# ESP32-S31 register map
Vendor: ESPRESSIF SYSTEMS (SHANGHAI) CO., LTD.; Series: ESP32 S-Series; File version: 1
CPU: RV32IMAFC r0p0, little endian, no MPU, FPU, 0 interrupt priority bits
Address unit: 32 bits
Registers are 32-bit, read-write, reset 0x0 unless marked. A register's access mark holds for its fields unless they carry their own. Offsets are from the block's base; [hi:lo] are bit positions.

## HP_PERI0_PMS — HP_PERI0_PMS Peripheral
Base 0x20505000
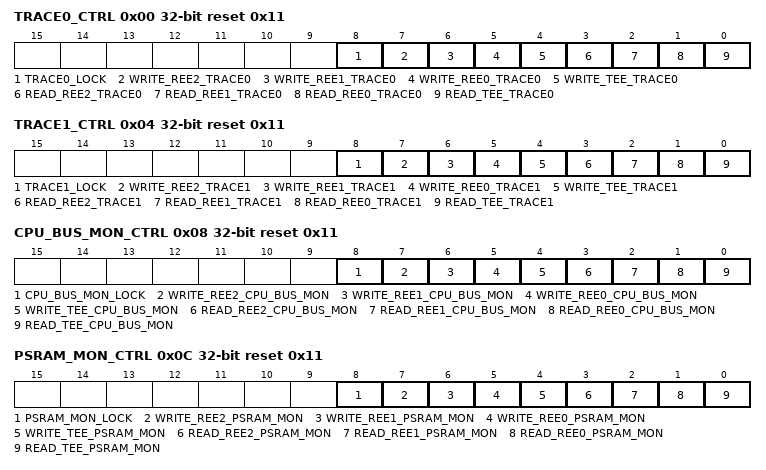
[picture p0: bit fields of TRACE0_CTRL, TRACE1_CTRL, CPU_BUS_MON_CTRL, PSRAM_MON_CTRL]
0x00 TRACE0_CTRL reset 0x11 — trace0 read/write control register
  [8] TRACE0_LOCK — Set 1 to lock trace0 peri_apm configuration
  [7] WRITE_REE2_TRACE0 — Configures trace0 registers write permission in ree2 mode.\\ 0: can not be write \\ 1: can be write \\
  [6] WRITE_REE1_TRACE0 — Configures trace0 registers write permission in ree1 mode.\\ 0: can not be write \\ 1: can be write \\
  [5] WRITE_REE0_TRACE0 — Configures trace0 registers write permission in ree0 mode.\\ 0: can not be write \\ 1: can be write \\
  [4] WRITE_TEE_TRACE0 — Configures trace0 registers write permission in tee mode.\\ 0: can not be write \\ 1: can be write \\
  [3] READ_REE2_TRACE0 — Configures trace0 registers read permission in ree2 mode.\\ 0: can not be read \\ 1: can be read \\
  [2] READ_REE1_TRACE0 — Configures trace0 registers read permission in ree1 mode.\\ 0: can not be read \\ 1: can be read \\
  [1] READ_REE0_TRACE0 — Configures trace0 registers read permission in ree0 mode.\\ 0: can not be read \\ 1: can be read \\
  [0] READ_TEE_TRACE0 — Configures trace0 registers read permission in tee mode.\\ 0: can not be read \\ 1: can be read \\
0x04 TRACE1_CTRL reset 0x11 — trace1 read/write control register
  [8] TRACE1_LOCK — Set 1 to lock trace1 peri_apm configuration
  [7] WRITE_REE2_TRACE1 — Configures trace1 registers write permission in ree2 mode.\\ 0: can not be write \\ 1: can be write \\
  [6] WRITE_REE1_TRACE1 — Configures trace1 registers write permission in ree1 mode.\\ 0: can not be write \\ 1: can be write \\
  [5] WRITE_REE0_TRACE1 — Configures trace1 registers write permission in ree0 mode.\\ 0: can not be write \\ 1: can be write \\
  [4] WRITE_TEE_TRACE1 — Configures trace1 registers write permission in tee mode.\\ 0: can not be write \\ 1: can be write \\
  [3] READ_REE2_TRACE1 — Configures trace1 registers read permission in ree2 mode.\\ 0: can not be read \\ 1: can be read \\
  [2] READ_REE1_TRACE1 — Configures trace1 registers read permission in ree1 mode.\\ 0: can not be read \\ 1: can be read \\
  [1] READ_REE0_TRACE1 — Configures trace1 registers read permission in ree0 mode.\\ 0: can not be read \\ 1: can be read \\
  [0] READ_TEE_TRACE1 — Configures trace1 registers read permission in tee mode.\\ 0: can not be read \\ 1: can be read \\
0x08 CPU_BUS_MON_CTRL reset 0x11 — cpu_bus_mon read/write control register
  [8] CPU_BUS_MON_LOCK — Set 1 to lock cpu_bus_mon peri_apm configuration
  [7] WRITE_REE2_CPU_BUS_MON — Configures cpu_bus_mon registers write permission in ree2 mode.\\ 0: can not be write \\ 1: can be write \\
  [6] WRITE_REE1_CPU_BUS_MON — Configures cpu_bus_mon registers write permission in ree1 mode.\\ 0: can not be write \\ 1: can be write \\
  [5] WRITE_REE0_CPU_BUS_MON — Configures cpu_bus_mon registers write permission in ree0 mode.\\ 0: can not be write \\ 1: can be write \\
  [4] WRITE_TEE_CPU_BUS_MON — Configures cpu_bus_mon registers write permission in tee mode.\\ 0: can not be write \\ 1: can be write \\
  [3] READ_REE2_CPU_BUS_MON — Configures cpu_bus_mon registers read permission in ree2 mode.\\ 0: can not be read \\ 1: can be read \\
  [2] READ_REE1_CPU_BUS_MON — Configures cpu_bus_mon registers read permission in ree1 mode.\\ 0: can not be read \\ 1: can be read \\
  [1] READ_REE0_CPU_BUS_MON — Configures cpu_bus_mon registers read permission in ree0 mode.\\ 0: can not be read \\ 1: can be read \\
  [0] READ_TEE_CPU_BUS_MON — Configures cpu_bus_mon registers read permission in tee mode.\\ 0: can not be read \\ 1: can be read \\
0x0C PSRAM_MON_CTRL reset 0x11 — psram_mon read/write control register
  [8] PSRAM_MON_LOCK — Set 1 to lock psram_mon peri_apm configuration
  [7] WRITE_REE2_PSRAM_MON — Configures psram_mon registers write permission in ree2 mode.\\ 0: can not be write \\ 1: can be write \\
  [6] WRITE_REE1_PSRAM_MON — Configures psram_mon registers write permission in ree1 mode.\\ 0: can not be write \\ 1: can be write \\
  [5] WRITE_REE0_PSRAM_MON — Configures psram_mon registers write permission in ree0 mode.\\ 0: can not be write \\ 1: can be write \\
  [4] WRITE_TEE_PSRAM_MON — Configures psram_mon registers write permission in tee mode.\\ 0: can not be write \\ 1: can be write \\
  [3] READ_REE2_PSRAM_MON — Configures psram_mon registers read permission in ree2 mode.\\ 0: can not be read \\ 1: can be read \\
  [2] READ_REE1_PSRAM_MON — Configures psram_mon registers read permission in ree1 mode.\\ 0: can not be read \\ 1: can be read \\
  [1] READ_REE0_PSRAM_MON — Configures psram_mon registers read permission in ree0 mode.\\ 0: can not be read \\ 1: can be read \\
  [0] READ_TEE_PSRAM_MON — Configures psram_mon registers read permission in tee mode.\\ 0: can not be read \\ 1: can be read \\
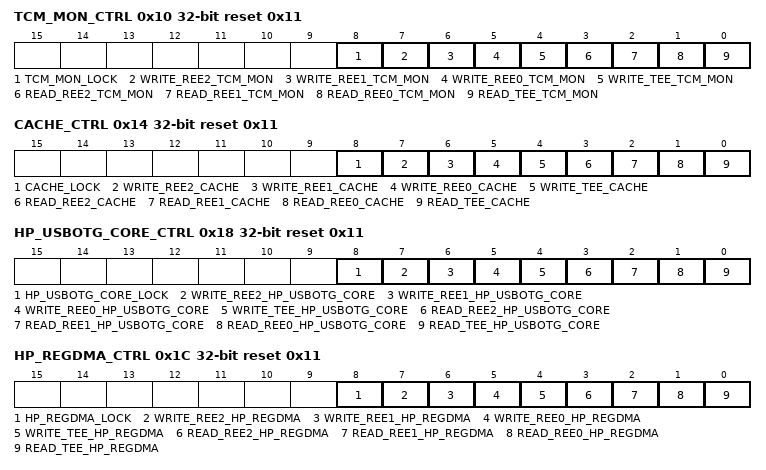
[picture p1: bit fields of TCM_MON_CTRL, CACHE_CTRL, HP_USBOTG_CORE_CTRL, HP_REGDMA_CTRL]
0x10 TCM_MON_CTRL reset 0x11 — tcm_mon read/write control register
  [8] TCM_MON_LOCK — Set 1 to lock tcm_mon peri_apm configuration
  [7] WRITE_REE2_TCM_MON — Configures tcm_mon registers write permission in ree2 mode.\\ 0: can not be write \\ 1: can be write \\
  [6] WRITE_REE1_TCM_MON — Configures tcm_mon registers write permission in ree1 mode.\\ 0: can not be write \\ 1: can be write \\
  [5] WRITE_REE0_TCM_MON — Configures tcm_mon registers write permission in ree0 mode.\\ 0: can not be write \\ 1: can be write \\
  [4] WRITE_TEE_TCM_MON — Configures tcm_mon registers write permission in tee mode.\\ 0: can not be write \\ 1: can be write \\
  [3] READ_REE2_TCM_MON — Configures tcm_mon registers read permission in ree2 mode.\\ 0: can not be read \\ 1: can be read \\
  [2] READ_REE1_TCM_MON — Configures tcm_mon registers read permission in ree1 mode.\\ 0: can not be read \\ 1: can be read \\
  [1] READ_REE0_TCM_MON — Configures tcm_mon registers read permission in ree0 mode.\\ 0: can not be read \\ 1: can be read \\
  [0] READ_TEE_TCM_MON — Configures tcm_mon registers read permission in tee mode.\\ 0: can not be read \\ 1: can be read \\
0x14 CACHE_CTRL reset 0x11 — cache read/write control register
  [8] CACHE_LOCK — Set 1 to lock cache peri_apm configuration
  [7] WRITE_REE2_CACHE — Configures cache registers write permission in ree2 mode.\\ 0: can not be write \\ 1: can be write \\
  [6] WRITE_REE1_CACHE — Configures cache registers write permission in ree1 mode.\\ 0: can not be write \\ 1: can be write \\
  [5] WRITE_REE0_CACHE — Configures cache registers write permission in ree0 mode.\\ 0: can not be write \\ 1: can be write \\
  [4] WRITE_TEE_CACHE — Configures cache registers write permission in tee mode.\\ 0: can not be write \\ 1: can be write \\
  [3] READ_REE2_CACHE — Configures cache registers read permission in ree2 mode.\\ 0: can not be read \\ 1: can be read \\
  [2] READ_REE1_CACHE — Configures cache registers read permission in ree1 mode.\\ 0: can not be read \\ 1: can be read \\
  [1] READ_REE0_CACHE — Configures cache registers read permission in ree0 mode.\\ 0: can not be read \\ 1: can be read \\
  [0] READ_TEE_CACHE — Configures cache registers read permission in tee mode.\\ 0: can not be read \\ 1: can be read \\
0x18 HP_USBOTG_CORE_CTRL reset 0x11 — hp_usbotg_core read/write control register
  [8] HP_USBOTG_CORE_LOCK — Set 1 to lock hp_usbotg_core peri_apm configuration
  [7] WRITE_REE2_HP_USBOTG_CORE — Configures hp_usbotg_core registers write permission in ree2 mode.\\ 0: can not be write \\ 1: can be write \\
  [6] WRITE_REE1_HP_USBOTG_CORE — Configures hp_usbotg_core registers write permission in ree1 mode.\\ 0: can not be write \\ 1: can be write \\
  [5] WRITE_REE0_HP_USBOTG_CORE — Configures hp_usbotg_core registers write permission in ree0 mode.\\ 0: can not be write \\ 1: can be write \\
  [4] WRITE_TEE_HP_USBOTG_CORE — Configures hp_usbotg_core registers write permission in tee mode.\\ 0: can not be write \\ 1: can be write \\
  [3] READ_REE2_HP_USBOTG_CORE — Configures hp_usbotg_core registers read permission in ree2 mode.\\ 0: can not be read \\ 1: can be read \\
  [2] READ_REE1_HP_USBOTG_CORE — Configures hp_usbotg_core registers read permission in ree1 mode.\\ 0: can not be read \\ 1: can be read \\
  [1] READ_REE0_HP_USBOTG_CORE — Configures hp_usbotg_core registers read permission in ree0 mode.\\ 0: can not be read \\ 1: can be read \\
  [0] READ_TEE_HP_USBOTG_CORE — Configures hp_usbotg_core registers read permission in tee mode.\\ 0: can not be read \\ 1: can be read \\
0x1C HP_REGDMA_CTRL reset 0x11 — hp_regdma read/write control register
  [8] HP_REGDMA_LOCK — Set 1 to lock hp_regdma peri_apm configuration
  [7] WRITE_REE2_HP_REGDMA — Configures hp_regdma registers write permission in ree2 mode.\\ 0: can not be write \\ 1: can be write \\
  [6] WRITE_REE1_HP_REGDMA — Configures hp_regdma registers write permission in ree1 mode.\\ 0: can not be write \\ 1: can be write \\
  [5] WRITE_REE0_HP_REGDMA — Configures hp_regdma registers write permission in ree0 mode.\\ 0: can not be write \\ 1: can be write \\
  [4] WRITE_TEE_HP_REGDMA — Configures hp_regdma registers write permission in tee mode.\\ 0: can not be write \\ 1: can be write \\
  [3] READ_REE2_HP_REGDMA — Configures hp_regdma registers read permission in ree2 mode.\\ 0: can not be read \\ 1: can be read \\
  [2] READ_REE1_HP_REGDMA — Configures hp_regdma registers read permission in ree1 mode.\\ 0: can not be read \\ 1: can be read \\
  [1] READ_REE0_HP_REGDMA — Configures hp_regdma registers read permission in ree0 mode.\\ 0: can not be read \\ 1: can be read \\
  [0] READ_TEE_HP_REGDMA — Configures hp_regdma registers read permission in tee mode.\\ 0: can not be read \\ 1: can be read \\
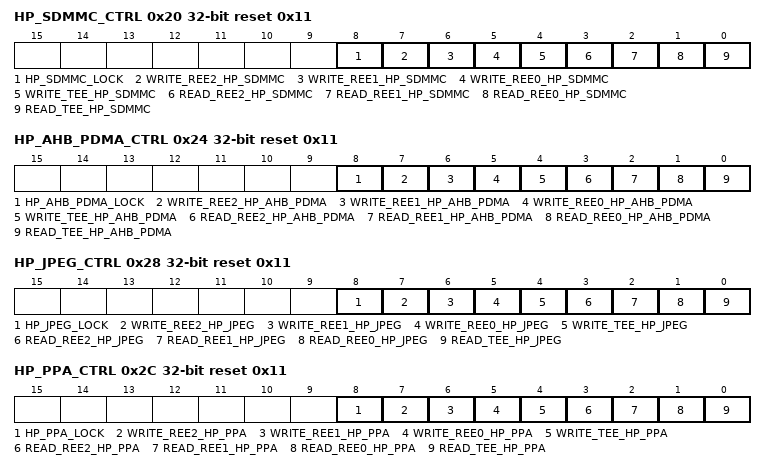
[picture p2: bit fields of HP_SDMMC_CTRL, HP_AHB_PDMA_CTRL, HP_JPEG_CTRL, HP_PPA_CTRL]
0x20 HP_SDMMC_CTRL reset 0x11 — hp_sdmmc read/write control register
  [8] HP_SDMMC_LOCK — Set 1 to lock hp_sdmmc peri_apm configuration
  [7] WRITE_REE2_HP_SDMMC — Configures hp_sdmmc registers write permission in ree2 mode.\\ 0: can not be write \\ 1: can be write \\
  [6] WRITE_REE1_HP_SDMMC — Configures hp_sdmmc registers write permission in ree1 mode.\\ 0: can not be write \\ 1: can be write \\
  [5] WRITE_REE0_HP_SDMMC — Configures hp_sdmmc registers write permission in ree0 mode.\\ 0: can not be write \\ 1: can be write \\
  [4] WRITE_TEE_HP_SDMMC — Configures hp_sdmmc registers write permission in tee mode.\\ 0: can not be write \\ 1: can be write \\
  [3] READ_REE2_HP_SDMMC — Configures hp_sdmmc registers read permission in ree2 mode.\\ 0: can not be read \\ 1: can be read \\
  [2] READ_REE1_HP_SDMMC — Configures hp_sdmmc registers read permission in ree1 mode.\\ 0: can not be read \\ 1: can be read \\
  [1] READ_REE0_HP_SDMMC — Configures hp_sdmmc registers read permission in ree0 mode.\\ 0: can not be read \\ 1: can be read \\
  [0] READ_TEE_HP_SDMMC — Configures hp_sdmmc registers read permission in tee mode.\\ 0: can not be read \\ 1: can be read \\
0x24 HP_AHB_PDMA_CTRL reset 0x11 — hp_ahb_pdma read/write control register
  [8] HP_AHB_PDMA_LOCK — Set 1 to lock hp_ahb_pdma peri_apm configuration
  [7] WRITE_REE2_HP_AHB_PDMA — Configures hp_ahb_pdma registers write permission in ree2 mode.\\ 0: can not be write \\ 1: can be write \\
  [6] WRITE_REE1_HP_AHB_PDMA — Configures hp_ahb_pdma registers write permission in ree1 mode.\\ 0: can not be write \\ 1: can be write \\
  [5] WRITE_REE0_HP_AHB_PDMA — Configures hp_ahb_pdma registers write permission in ree0 mode.\\ 0: can not be write \\ 1: can be write \\
  [4] WRITE_TEE_HP_AHB_PDMA — Configures hp_ahb_pdma registers write permission in tee mode.\\ 0: can not be write \\ 1: can be write \\
  [3] READ_REE2_HP_AHB_PDMA — Configures hp_ahb_pdma registers read permission in ree2 mode.\\ 0: can not be read \\ 1: can be read \\
  [2] READ_REE1_HP_AHB_PDMA — Configures hp_ahb_pdma registers read permission in ree1 mode.\\ 0: can not be read \\ 1: can be read \\
  [1] READ_REE0_HP_AHB_PDMA — Configures hp_ahb_pdma registers read permission in ree0 mode.\\ 0: can not be read \\ 1: can be read \\
  [0] READ_TEE_HP_AHB_PDMA — Configures hp_ahb_pdma registers read permission in tee mode.\\ 0: can not be read \\ 1: can be read \\
0x28 HP_JPEG_CTRL reset 0x11 — hp_jpeg read/write control register
  [8] HP_JPEG_LOCK — Set 1 to lock hp_jpeg peri_apm configuration
  [7] WRITE_REE2_HP_JPEG — Configures hp_jpeg registers write permission in ree2 mode.\\ 0: can not be write \\ 1: can be write \\
  [6] WRITE_REE1_HP_JPEG — Configures hp_jpeg registers write permission in ree1 mode.\\ 0: can not be write \\ 1: can be write \\
  [5] WRITE_REE0_HP_JPEG — Configures hp_jpeg registers write permission in ree0 mode.\\ 0: can not be write \\ 1: can be write \\
  [4] WRITE_TEE_HP_JPEG — Configures hp_jpeg registers write permission in tee mode.\\ 0: can not be write \\ 1: can be write \\
  [3] READ_REE2_HP_JPEG — Configures hp_jpeg registers read permission in ree2 mode.\\ 0: can not be read \\ 1: can be read \\
  [2] READ_REE1_HP_JPEG — Configures hp_jpeg registers read permission in ree1 mode.\\ 0: can not be read \\ 1: can be read \\
  [1] READ_REE0_HP_JPEG — Configures hp_jpeg registers read permission in ree0 mode.\\ 0: can not be read \\ 1: can be read \\
  [0] READ_TEE_HP_JPEG — Configures hp_jpeg registers read permission in tee mode.\\ 0: can not be read \\ 1: can be read \\
0x2C HP_PPA_CTRL reset 0x11 — hp_ppa read/write control register
  [8] HP_PPA_LOCK — Set 1 to lock hp_ppa peri_apm configuration
  [7] WRITE_REE2_HP_PPA — Configures hp_ppa registers write permission in ree2 mode.\\ 0: can not be write \\ 1: can be write \\
  [6] WRITE_REE1_HP_PPA — Configures hp_ppa registers write permission in ree1 mode.\\ 0: can not be write \\ 1: can be write \\
  [5] WRITE_REE0_HP_PPA — Configures hp_ppa registers write permission in ree0 mode.\\ 0: can not be write \\ 1: can be write \\
  [4] WRITE_TEE_HP_PPA — Configures hp_ppa registers write permission in tee mode.\\ 0: can not be write \\ 1: can be write \\
  [3] READ_REE2_HP_PPA — Configures hp_ppa registers read permission in ree2 mode.\\ 0: can not be read \\ 1: can be read \\
  [2] READ_REE1_HP_PPA — Configures hp_ppa registers read permission in ree1 mode.\\ 0: can not be read \\ 1: can be read \\
  [1] READ_REE0_HP_PPA — Configures hp_ppa registers read permission in ree0 mode.\\ 0: can not be read \\ 1: can be read \\
  [0] READ_TEE_HP_PPA — Configures hp_ppa registers read permission in tee mode.\\ 0: can not be read \\ 1: can be read \\
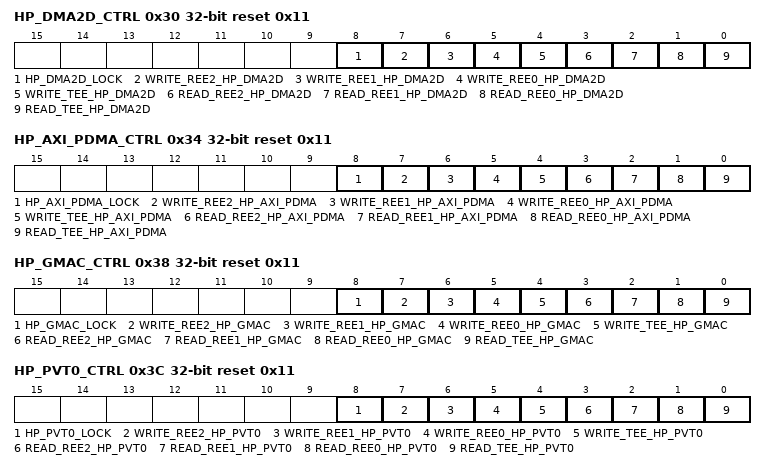
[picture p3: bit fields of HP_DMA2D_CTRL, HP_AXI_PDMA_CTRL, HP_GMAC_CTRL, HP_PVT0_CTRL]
0x30 HP_DMA2D_CTRL reset 0x11 — hp_dma2d read/write control register
  [8] HP_DMA2D_LOCK — Set 1 to lock hp_dma2d peri_apm configuration
  [7] WRITE_REE2_HP_DMA2D — Configures hp_dma2d registers write permission in ree2 mode.\\ 0: can not be write \\ 1: can be write \\
  [6] WRITE_REE1_HP_DMA2D — Configures hp_dma2d registers write permission in ree1 mode.\\ 0: can not be write \\ 1: can be write \\
  [5] WRITE_REE0_HP_DMA2D — Configures hp_dma2d registers write permission in ree0 mode.\\ 0: can not be write \\ 1: can be write \\
  [4] WRITE_TEE_HP_DMA2D — Configures hp_dma2d registers write permission in tee mode.\\ 0: can not be write \\ 1: can be write \\
  [3] READ_REE2_HP_DMA2D — Configures hp_dma2d registers read permission in ree2 mode.\\ 0: can not be read \\ 1: can be read \\
  [2] READ_REE1_HP_DMA2D — Configures hp_dma2d registers read permission in ree1 mode.\\ 0: can not be read \\ 1: can be read \\
  [1] READ_REE0_HP_DMA2D — Configures hp_dma2d registers read permission in ree0 mode.\\ 0: can not be read \\ 1: can be read \\
  [0] READ_TEE_HP_DMA2D — Configures hp_dma2d registers read permission in tee mode.\\ 0: can not be read \\ 1: can be read \\
0x34 HP_AXI_PDMA_CTRL reset 0x11 — hp_axi_pdma read/write control register
  [8] HP_AXI_PDMA_LOCK — Set 1 to lock hp_axi_pdma peri_apm configuration
  [7] WRITE_REE2_HP_AXI_PDMA — Configures hp_axi_pdma registers write permission in ree2 mode.\\ 0: can not be write \\ 1: can be write \\
  [6] WRITE_REE1_HP_AXI_PDMA — Configures hp_axi_pdma registers write permission in ree1 mode.\\ 0: can not be write \\ 1: can be write \\
  [5] WRITE_REE0_HP_AXI_PDMA — Configures hp_axi_pdma registers write permission in ree0 mode.\\ 0: can not be write \\ 1: can be write \\
  [4] WRITE_TEE_HP_AXI_PDMA — Configures hp_axi_pdma registers write permission in tee mode.\\ 0: can not be write \\ 1: can be write \\
  [3] READ_REE2_HP_AXI_PDMA — Configures hp_axi_pdma registers read permission in ree2 mode.\\ 0: can not be read \\ 1: can be read \\
  [2] READ_REE1_HP_AXI_PDMA — Configures hp_axi_pdma registers read permission in ree1 mode.\\ 0: can not be read \\ 1: can be read \\
  [1] READ_REE0_HP_AXI_PDMA — Configures hp_axi_pdma registers read permission in ree0 mode.\\ 0: can not be read \\ 1: can be read \\
  [0] READ_TEE_HP_AXI_PDMA — Configures hp_axi_pdma registers read permission in tee mode.\\ 0: can not be read \\ 1: can be read \\
0x38 HP_GMAC_CTRL reset 0x11 — hp_gmac read/write control register
  [8] HP_GMAC_LOCK — Set 1 to lock hp_gmac peri_apm configuration
  [7] WRITE_REE2_HP_GMAC — Configures hp_gmac registers write permission in ree2 mode.\\ 0: can not be write \\ 1: can be write \\
  [6] WRITE_REE1_HP_GMAC — Configures hp_gmac registers write permission in ree1 mode.\\ 0: can not be write \\ 1: can be write \\
  [5] WRITE_REE0_HP_GMAC — Configures hp_gmac registers write permission in ree0 mode.\\ 0: can not be write \\ 1: can be write \\
  [4] WRITE_TEE_HP_GMAC — Configures hp_gmac registers write permission in tee mode.\\ 0: can not be write \\ 1: can be write \\
  [3] READ_REE2_HP_GMAC — Configures hp_gmac registers read permission in ree2 mode.\\ 0: can not be read \\ 1: can be read \\
  [2] READ_REE1_HP_GMAC — Configures hp_gmac registers read permission in ree1 mode.\\ 0: can not be read \\ 1: can be read \\
  [1] READ_REE0_HP_GMAC — Configures hp_gmac registers read permission in ree0 mode.\\ 0: can not be read \\ 1: can be read \\
  [0] READ_TEE_HP_GMAC — Configures hp_gmac registers read permission in tee mode.\\ 0: can not be read \\ 1: can be read \\
0x3C HP_PVT0_CTRL reset 0x11 — hp_pvt0 read/write control register
  [8] HP_PVT0_LOCK — Set 1 to lock hp_pvt0 peri_apm configuration
  [7] WRITE_REE2_HP_PVT0 — Configures hp_pvt0 registers write permission in ree2 mode.\\ 0: can not be write \\ 1: can be write \\
  [6] WRITE_REE1_HP_PVT0 — Configures hp_pvt0 registers write permission in ree1 mode.\\ 0: can not be write \\ 1: can be write \\
  [5] WRITE_REE0_HP_PVT0 — Configures hp_pvt0 registers write permission in ree0 mode.\\ 0: can not be write \\ 1: can be write \\
  [4] WRITE_TEE_HP_PVT0 — Configures hp_pvt0 registers write permission in tee mode.\\ 0: can not be write \\ 1: can be write \\
  [3] READ_REE2_HP_PVT0 — Configures hp_pvt0 registers read permission in ree2 mode.\\ 0: can not be read \\ 1: can be read \\
  [2] READ_REE1_HP_PVT0 — Configures hp_pvt0 registers read permission in ree1 mode.\\ 0: can not be read \\ 1: can be read \\
  [1] READ_REE0_HP_PVT0 — Configures hp_pvt0 registers read permission in ree0 mode.\\ 0: can not be read \\ 1: can be read \\
  [0] READ_TEE_HP_PVT0 — Configures hp_pvt0 registers read permission in tee mode.\\ 0: can not be read \\ 1: can be read \\
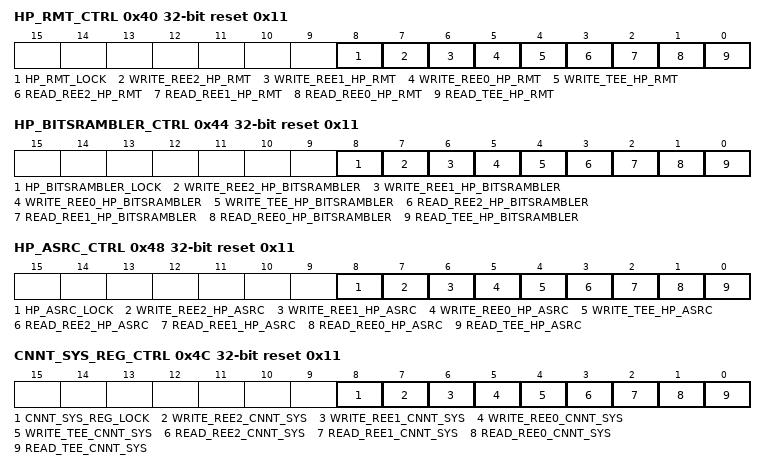
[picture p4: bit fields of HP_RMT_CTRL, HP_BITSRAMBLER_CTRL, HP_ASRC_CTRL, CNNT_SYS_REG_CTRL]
0x40 HP_RMT_CTRL reset 0x11 — hp_rmt read/write control register
  [8] HP_RMT_LOCK — Set 1 to lock hp_rmt peri_apm configuration
  [7] WRITE_REE2_HP_RMT — Configures hp_rmt registers write permission in ree2 mode.\\ 0: can not be write \\ 1: can be write \\
  [6] WRITE_REE1_HP_RMT — Configures hp_rmt registers write permission in ree1 mode.\\ 0: can not be write \\ 1: can be write \\
  [5] WRITE_REE0_HP_RMT — Configures hp_rmt registers write permission in ree0 mode.\\ 0: can not be write \\ 1: can be write \\
  [4] WRITE_TEE_HP_RMT — Configures hp_rmt registers write permission in tee mode.\\ 0: can not be write \\ 1: can be write \\
  [3] READ_REE2_HP_RMT — Configures hp_rmt registers read permission in ree2 mode.\\ 0: can not be read \\ 1: can be read \\
  [2] READ_REE1_HP_RMT — Configures hp_rmt registers read permission in ree1 mode.\\ 0: can not be read \\ 1: can be read \\
  [1] READ_REE0_HP_RMT — Configures hp_rmt registers read permission in ree0 mode.\\ 0: can not be read \\ 1: can be read \\
  [0] READ_TEE_HP_RMT — Configures hp_rmt registers read permission in tee mode.\\ 0: can not be read \\ 1: can be read \\
0x44 HP_BITSRAMBLER_CTRL reset 0x11 — hp_bitsrambler read/write control register
  [8] HP_BITSRAMBLER_LOCK — Set 1 to lock hp_bitsrambler peri_apm configuration
  [7] WRITE_REE2_HP_BITSRAMBLER — Configures hp_bitsrambler registers write permission in ree2 mode.\\ 0: can not be write \\ 1: can be write \\
  [6] WRITE_REE1_HP_BITSRAMBLER — Configures hp_bitsrambler registers write permission in ree1 mode.\\ 0: can not be write \\ 1: can be write \\
  [5] WRITE_REE0_HP_BITSRAMBLER — Configures hp_bitsrambler registers write permission in ree0 mode.\\ 0: can not be write \\ 1: can be write \\
  [4] WRITE_TEE_HP_BITSRAMBLER — Configures hp_bitsrambler registers write permission in tee mode.\\ 0: can not be write \\ 1: can be write \\
  [3] READ_REE2_HP_BITSRAMBLER — Configures hp_bitsrambler registers read permission in ree2 mode.\\ 0: can not be read \\ 1: can be read \\
  [2] READ_REE1_HP_BITSRAMBLER — Configures hp_bitsrambler registers read permission in ree1 mode.\\ 0: can not be read \\ 1: can be read \\
  [1] READ_REE0_HP_BITSRAMBLER — Configures hp_bitsrambler registers read permission in ree0 mode.\\ 0: can not be read \\ 1: can be read \\
  [0] READ_TEE_HP_BITSRAMBLER — Configures hp_bitsrambler registers read permission in tee mode.\\ 0: can not be read \\ 1: can be read \\
0x48 HP_ASRC_CTRL reset 0x11 — hp_asrc read/write control register
  [8] HP_ASRC_LOCK — Set 1 to lock hp_asrc peri_apm configuration
  [7] WRITE_REE2_HP_ASRC — Configures hp_asrc registers write permission in ree2 mode.\\ 0: can not be write \\ 1: can be write \\
  [6] WRITE_REE1_HP_ASRC — Configures hp_asrc registers write permission in ree1 mode.\\ 0: can not be write \\ 1: can be write \\
  [5] WRITE_REE0_HP_ASRC — Configures hp_asrc registers write permission in ree0 mode.\\ 0: can not be write \\ 1: can be write \\
  [4] WRITE_TEE_HP_ASRC — Configures hp_asrc registers write permission in tee mode.\\ 0: can not be write \\ 1: can be write \\
  [3] READ_REE2_HP_ASRC — Configures hp_asrc registers read permission in ree2 mode.\\ 0: can not be read \\ 1: can be read \\
  [2] READ_REE1_HP_ASRC — Configures hp_asrc registers read permission in ree1 mode.\\ 0: can not be read \\ 1: can be read \\
  [1] READ_REE0_HP_ASRC — Configures hp_asrc registers read permission in ree0 mode.\\ 0: can not be read \\ 1: can be read \\
  [0] READ_TEE_HP_ASRC — Configures hp_asrc registers read permission in tee mode.\\ 0: can not be read \\ 1: can be read \\
0x4C CNNT_SYS_REG_CTRL reset 0x11 — cnnt_sys_reg read/write control register
  [8] CNNT_SYS_REG_LOCK — Set 1 to lock cnnt_sys_reg peri_apm configuration
  [7] WRITE_REE2_CNNT_SYS — Configures cnnt_sys_reg registers write permission in ree2 mode.\\ 0: can not be write \\ 1: can be write \\
  [6] WRITE_REE1_CNNT_SYS — Configures cnnt_sys_reg registers write permission in ree1 mode.\\ 0: can not be write \\ 1: can be write \\
  [5] WRITE_REE0_CNNT_SYS — Configures cnnt_sys_reg registers write permission in ree0 mode.\\ 0: can not be write \\ 1: can be write \\
  [4] WRITE_TEE_CNNT_SYS — Configures cnnt_sys_reg registers write permission in tee mode.\\ 0: can not be write \\ 1: can be write \\
  [3] READ_REE2_CNNT_SYS — Configures cnnt_sys_reg registers read permission in ree2 mode.\\ 0: can not be read \\ 1: can be read \\
  [2] READ_REE1_CNNT_SYS — Configures cnnt_sys_reg registers read permission in ree1 mode.\\ 0: can not be read \\ 1: can be read \\
  [1] READ_REE0_CNNT_SYS — Configures cnnt_sys_reg registers read permission in ree0 mode.\\ 0: can not be read \\ 1: can be read \\
  [0] READ_TEE_CNNT_SYS — Configures cnnt_sys_reg registers read permission in tee mode.\\ 0: can not be read \\ 1: can be read \\
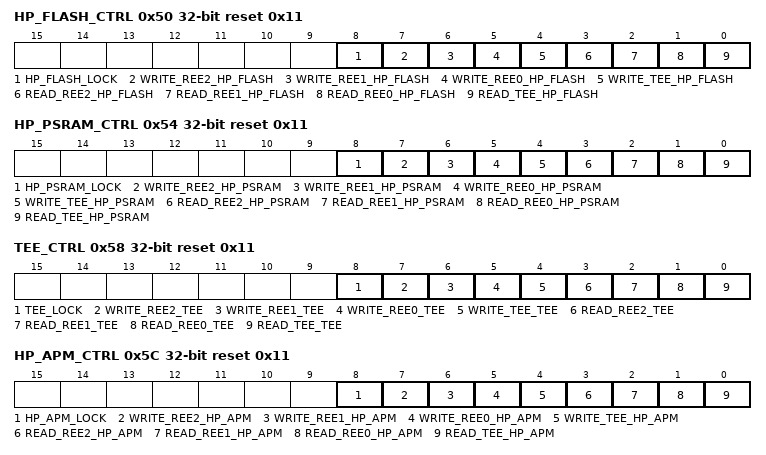
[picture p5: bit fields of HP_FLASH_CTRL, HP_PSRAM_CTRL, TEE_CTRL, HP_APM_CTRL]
0x50 HP_FLASH_CTRL reset 0x11 — hp_flash read/write control register
  [8] HP_FLASH_LOCK — Set 1 to lock hp_flash peri_apm configuration
  [7] WRITE_REE2_HP_FLASH — Configures hp_flash registers write permission in ree2 mode.\\ 0: can not be write \\ 1: can be write \\
  [6] WRITE_REE1_HP_FLASH — Configures hp_flash registers write permission in ree1 mode.\\ 0: can not be write \\ 1: can be write \\
  [5] WRITE_REE0_HP_FLASH — Configures hp_flash registers write permission in ree0 mode.\\ 0: can not be write \\ 1: can be write \\
  [4] WRITE_TEE_HP_FLASH — Configures hp_flash registers write permission in tee mode.\\ 0: can not be write \\ 1: can be write \\
  [3] READ_REE2_HP_FLASH — Configures hp_flash registers read permission in ree2 mode.\\ 0: can not be read \\ 1: can be read \\
  [2] READ_REE1_HP_FLASH — Configures hp_flash registers read permission in ree1 mode.\\ 0: can not be read \\ 1: can be read \\
  [1] READ_REE0_HP_FLASH — Configures hp_flash registers read permission in ree0 mode.\\ 0: can not be read \\ 1: can be read \\
  [0] READ_TEE_HP_FLASH — Configures hp_flash registers read permission in tee mode.\\ 0: can not be read \\ 1: can be read \\
0x54 HP_PSRAM_CTRL reset 0x11 — hp_psram read/write control register
  [8] HP_PSRAM_LOCK — Set 1 to lock hp_psram peri_apm configuration
  [7] WRITE_REE2_HP_PSRAM — Configures hp_psram registers write permission in ree2 mode.\\ 0: can not be write \\ 1: can be write \\
  [6] WRITE_REE1_HP_PSRAM — Configures hp_psram registers write permission in ree1 mode.\\ 0: can not be write \\ 1: can be write \\
  [5] WRITE_REE0_HP_PSRAM — Configures hp_psram registers write permission in ree0 mode.\\ 0: can not be write \\ 1: can be write \\
  [4] WRITE_TEE_HP_PSRAM — Configures hp_psram registers write permission in tee mode.\\ 0: can not be write \\ 1: can be write \\
  [3] READ_REE2_HP_PSRAM — Configures hp_psram registers read permission in ree2 mode.\\ 0: can not be read \\ 1: can be read \\
  [2] READ_REE1_HP_PSRAM — Configures hp_psram registers read permission in ree1 mode.\\ 0: can not be read \\ 1: can be read \\
  [1] READ_REE0_HP_PSRAM — Configures hp_psram registers read permission in ree0 mode.\\ 0: can not be read \\ 1: can be read \\
  [0] READ_TEE_HP_PSRAM — Configures hp_psram registers read permission in tee mode.\\ 0: can not be read \\ 1: can be read \\
0x58 TEE_CTRL access per field reset 0x11 — tee read/write control register
  [8] TEE_LOCK rw — Set 1 to lock tee peri_apm configuration
  [7] WRITE_REE2_TEE ro — Configures tee registers write permission in ree2 mode.\\ 0: can not be write \\ 1: can be write \\
  [6] WRITE_REE1_TEE ro — Configures tee registers write permission in ree1 mode.\\ 0: can not be write \\ 1: can be write \\
  [5] WRITE_REE0_TEE ro — Configures tee registers write permission in ree0 mode.\\ 0: can not be write \\ 1: can be write \\
  [4] WRITE_TEE_TEE rw — Configures tee registers write permission in tee mode.\\ 0: can not be write \\ 1: can be write \\
  [3] READ_REE2_TEE ro — Configures tee registers read permission in ree2 mode.\\ 0: can not be read \\ 1: can be read \\
  [2] READ_REE1_TEE ro — Configures tee registers read permission in ree1 mode.\\ 0: can not be read \\ 1: can be read \\
  [1] READ_REE0_TEE ro — Configures tee registers read permission in ree0 mode.\\ 0: can not be read \\ 1: can be read \\
  [0] READ_TEE_TEE rw — Configures tee registers read permission in tee mode.\\ 0: can not be read \\ 1: can be read \\
0x5C HP_APM_CTRL access per field reset 0x11 — hp_apm read/write control register
  [8] HP_APM_LOCK rw — Set 1 to lock hp_apm peri_apm configuration
  [7] WRITE_REE2_HP_APM ro — Configures hp_apm registers write permission in ree2 mode.\\ 0: can not be write \\ 1: can be write \\
  [6] WRITE_REE1_HP_APM ro — Configures hp_apm registers write permission in ree1 mode.\\ 0: can not be write \\ 1: can be write \\
  [5] WRITE_REE0_HP_APM ro — Configures hp_apm registers write permission in ree0 mode.\\ 0: can not be write \\ 1: can be write \\
  [4] WRITE_TEE_HP_APM rw — Configures hp_apm registers write permission in tee mode.\\ 0: can not be write \\ 1: can be write \\
  [3] READ_REE2_HP_APM ro — Configures hp_apm registers read permission in ree2 mode.\\ 0: can not be read \\ 1: can be read \\
  [2] READ_REE1_HP_APM ro — Configures hp_apm registers read permission in ree1 mode.\\ 0: can not be read \\ 1: can be read \\
  [1] READ_REE0_HP_APM ro — Configures hp_apm registers read permission in ree0 mode.\\ 0: can not be read \\ 1: can be read \\
  [0] READ_TEE_HP_APM rw — Configures hp_apm registers read permission in tee mode.\\ 0: can not be read \\ 1: can be read \\
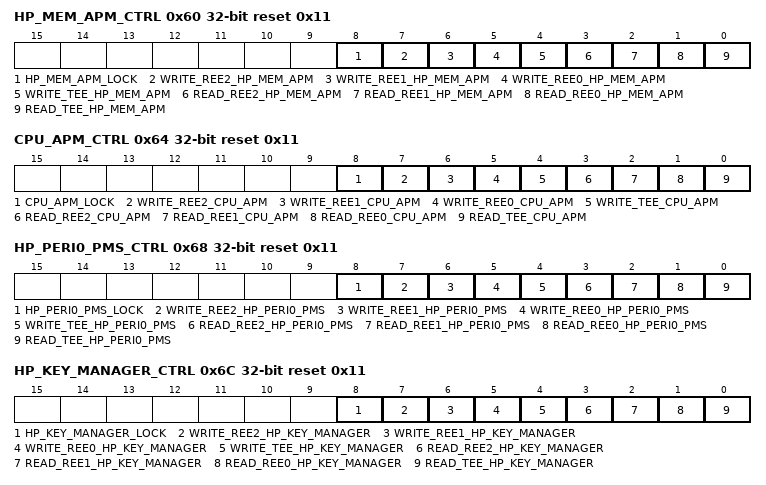
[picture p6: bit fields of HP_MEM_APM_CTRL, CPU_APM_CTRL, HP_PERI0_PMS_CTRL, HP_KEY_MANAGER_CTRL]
0x60 HP_MEM_APM_CTRL access per field reset 0x11 — hp_mem_apm read/write control register
  [8] HP_MEM_APM_LOCK rw — Set 1 to lock hp_mem_apm peri_apm configuration
  [7] WRITE_REE2_HP_MEM_APM ro — Configures hp_mem_apm registers write permission in ree2 mode.\\ 0: can not be write \\ 1: can be write \\
  [6] WRITE_REE1_HP_MEM_APM ro — Configures hp_mem_apm registers write permission in ree1 mode.\\ 0: can not be write \\ 1: can be write \\
  [5] WRITE_REE0_HP_MEM_APM ro — Configures hp_mem_apm registers write permission in ree0 mode.\\ 0: can not be write \\ 1: can be write \\
  [4] WRITE_TEE_HP_MEM_APM rw — Configures hp_mem_apm registers write permission in tee mode.\\ 0: can not be write \\ 1: can be write \\
  [3] READ_REE2_HP_MEM_APM ro — Configures hp_mem_apm registers read permission in ree2 mode.\\ 0: can not be read \\ 1: can be read \\
  [2] READ_REE1_HP_MEM_APM ro — Configures hp_mem_apm registers read permission in ree1 mode.\\ 0: can not be read \\ 1: can be read \\
  [1] READ_REE0_HP_MEM_APM ro — Configures hp_mem_apm registers read permission in ree0 mode.\\ 0: can not be read \\ 1: can be read \\
  [0] READ_TEE_HP_MEM_APM rw — Configures hp_mem_apm registers read permission in tee mode.\\ 0: can not be read \\ 1: can be read \\
0x64 CPU_APM_CTRL access per field reset 0x11 — cpu_apm read/write control register
  [8] CPU_APM_LOCK rw — Set 1 to lock cpu_apm peri_apm configuration
  [7] WRITE_REE2_CPU_APM ro — Configures cpu_apm registers write permission in ree2 mode.\\ 0: can not be write \\ 1: can be write \\
  [6] WRITE_REE1_CPU_APM ro — Configures cpu_apm registers write permission in ree1 mode.\\ 0: can not be write \\ 1: can be write \\
  [5] WRITE_REE0_CPU_APM ro — Configures cpu_apm registers write permission in ree0 mode.\\ 0: can not be write \\ 1: can be write \\
  [4] WRITE_TEE_CPU_APM rw — Configures cpu_apm registers write permission in tee mode.\\ 0: can not be write \\ 1: can be write \\
  [3] READ_REE2_CPU_APM ro — Configures cpu_apm registers read permission in ree2 mode.\\ 0: can not be read \\ 1: can be read \\
  [2] READ_REE1_CPU_APM ro — Configures cpu_apm registers read permission in ree1 mode.\\ 0: can not be read \\ 1: can be read \\
  [1] READ_REE0_CPU_APM ro — Configures cpu_apm registers read permission in ree0 mode.\\ 0: can not be read \\ 1: can be read \\
  [0] READ_TEE_CPU_APM rw — Configures cpu_apm registers read permission in tee mode.\\ 0: can not be read \\ 1: can be read \\
0x68 HP_PERI0_PMS_CTRL access per field reset 0x11 — hp_peri0_pms read/write control register
  [8] HP_PERI0_PMS_LOCK rw — Set 1 to lock hp_peri0_pms peri_apm configuration
  [7] WRITE_REE2_HP_PERI0_PMS ro — Configures hp_peri0_pms registers write permission in ree2 mode.\\ 0: can not be write \\ 1: can be write \\
  [6] WRITE_REE1_HP_PERI0_PMS ro — Configures hp_peri0_pms registers write permission in ree1 mode.\\ 0: can not be write \\ 1: can be write \\
  [5] WRITE_REE0_HP_PERI0_PMS ro — Configures hp_peri0_pms registers write permission in ree0 mode.\\ 0: can not be write \\ 1: can be write \\
  [4] WRITE_TEE_HP_PERI0_PMS rw — Configures hp_peri0_pms registers write permission in tee mode.\\ 0: can not be write \\ 1: can be write \\
  [3] READ_REE2_HP_PERI0_PMS ro — Configures hp_peri0_pms registers read permission in ree2 mode.\\ 0: can not be read \\ 1: can be read \\
  [2] READ_REE1_HP_PERI0_PMS ro — Configures hp_peri0_pms registers read permission in ree1 mode.\\ 0: can not be read \\ 1: can be read \\
  [1] READ_REE0_HP_PERI0_PMS ro — Configures hp_peri0_pms registers read permission in ree0 mode.\\ 0: can not be read \\ 1: can be read \\
  [0] READ_TEE_HP_PERI0_PMS rw — Configures hp_peri0_pms registers read permission in tee mode.\\ 0: can not be read \\ 1: can be read \\
0x6C HP_KEY_MANAGER_CTRL reset 0x11 — hp_key_manager read/write control register
  [8] HP_KEY_MANAGER_LOCK — Set 1 to lock hp_key_manager peri_apm configuration
  [7] WRITE_REE2_HP_KEY_MANAGER — Configures hp_key_manager registers write permission in ree2 mode.\\ 0: can not be write \\ 1: can be write \\
  [6] WRITE_REE1_HP_KEY_MANAGER — Configures hp_key_manager registers write permission in ree1 mode.\\ 0: can not be write \\ 1: can be write \\
  [5] WRITE_REE0_HP_KEY_MANAGER — Configures hp_key_manager registers write permission in ree0 mode.\\ 0: can not be write \\ 1: can be write \\
  [4] WRITE_TEE_HP_KEY_MANAGER — Configures hp_key_manager registers write permission in tee mode.\\ 0: can not be write \\ 1: can be write \\
  [3] READ_REE2_HP_KEY_MANAGER — Configures hp_key_manager registers read permission in ree2 mode.\\ 0: can not be read \\ 1: can be read \\
  [2] READ_REE1_HP_KEY_MANAGER — Configures hp_key_manager registers read permission in ree1 mode.\\ 0: can not be read \\ 1: can be read \\
  [1] READ_REE0_HP_KEY_MANAGER — Configures hp_key_manager registers read permission in ree0 mode.\\ 0: can not be read \\ 1: can be read \\
  [0] READ_TEE_HP_KEY_MANAGER — Configures hp_key_manager registers read permission in tee mode.\\ 0: can not be read \\ 1: can be read \\
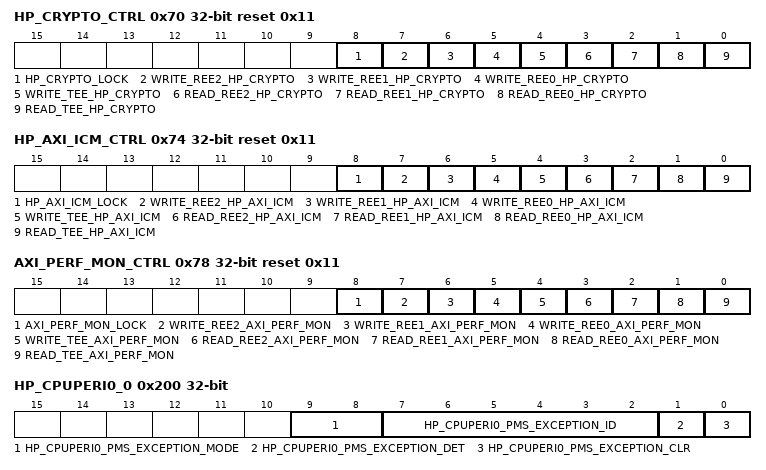
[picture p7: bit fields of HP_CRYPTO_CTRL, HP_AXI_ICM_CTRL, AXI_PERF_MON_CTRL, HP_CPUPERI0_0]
0x70 HP_CRYPTO_CTRL reset 0x11 — hp_crypto read/write control register
  [8] HP_CRYPTO_LOCK — Set 1 to lock hp_crypto peri_apm configuration
  [7] WRITE_REE2_HP_CRYPTO — Configures hp_crypto registers write permission in ree2 mode.\\ 0: can not be write \\ 1: can be write \\
  [6] WRITE_REE1_HP_CRYPTO — Configures hp_crypto registers write permission in ree1 mode.\\ 0: can not be write \\ 1: can be write \\
  [5] WRITE_REE0_HP_CRYPTO — Configures hp_crypto registers write permission in ree0 mode.\\ 0: can not be write \\ 1: can be write \\
  [4] WRITE_TEE_HP_CRYPTO — Configures hp_crypto registers write permission in tee mode.\\ 0: can not be write \\ 1: can be write \\
  [3] READ_REE2_HP_CRYPTO — Configures hp_crypto registers read permission in ree2 mode.\\ 0: can not be read \\ 1: can be read \\
  [2] READ_REE1_HP_CRYPTO — Configures hp_crypto registers read permission in ree1 mode.\\ 0: can not be read \\ 1: can be read \\
  [1] READ_REE0_HP_CRYPTO — Configures hp_crypto registers read permission in ree0 mode.\\ 0: can not be read \\ 1: can be read \\
  [0] READ_TEE_HP_CRYPTO — Configures hp_crypto registers read permission in tee mode.\\ 0: can not be read \\ 1: can be read \\
0x74 HP_AXI_ICM_CTRL reset 0x11 — hp_axi_icm read/write control register
  [8] HP_AXI_ICM_LOCK — Set 1 to lock hp_axi_icm peri_apm configuration
  [7] WRITE_REE2_HP_AXI_ICM — Configures hp_axi_icm registers write permission in ree2 mode.\\ 0: can not be write \\ 1: can be write \\
  [6] WRITE_REE1_HP_AXI_ICM — Configures hp_axi_icm registers write permission in ree1 mode.\\ 0: can not be write \\ 1: can be write \\
  [5] WRITE_REE0_HP_AXI_ICM — Configures hp_axi_icm registers write permission in ree0 mode.\\ 0: can not be write \\ 1: can be write \\
  [4] WRITE_TEE_HP_AXI_ICM — Configures hp_axi_icm registers write permission in tee mode.\\ 0: can not be write \\ 1: can be write \\
  [3] READ_REE2_HP_AXI_ICM — Configures hp_axi_icm registers read permission in ree2 mode.\\ 0: can not be read \\ 1: can be read \\
  [2] READ_REE1_HP_AXI_ICM — Configures hp_axi_icm registers read permission in ree1 mode.\\ 0: can not be read \\ 1: can be read \\
  [1] READ_REE0_HP_AXI_ICM — Configures hp_axi_icm registers read permission in ree0 mode.\\ 0: can not be read \\ 1: can be read \\
  [0] READ_TEE_HP_AXI_ICM — Configures hp_axi_icm registers read permission in tee mode.\\ 0: can not be read \\ 1: can be read \\
0x78 AXI_PERF_MON_CTRL reset 0x11 — axi_perf_mon read/write control register
  [8] AXI_PERF_MON_LOCK — Set 1 to lock axi_perf_mon peri_apm configuration
  [7] WRITE_REE2_AXI_PERF_MON — Configures axi_perf_mon registers write permission in ree2 mode.\\ 0: can not be write \\ 1: can be write \\
  [6] WRITE_REE1_AXI_PERF_MON — Configures axi_perf_mon registers write permission in ree1 mode.\\ 0: can not be write \\ 1: can be write \\
  [5] WRITE_REE0_AXI_PERF_MON — Configures axi_perf_mon registers write permission in ree0 mode.\\ 0: can not be write \\ 1: can be write \\
  [4] WRITE_TEE_AXI_PERF_MON — Configures axi_perf_mon registers write permission in tee mode.\\ 0: can not be write \\ 1: can be write \\
  [3] READ_REE2_AXI_PERF_MON — Configures axi_perf_mon registers read permission in ree2 mode.\\ 0: can not be read \\ 1: can be read \\
  [2] READ_REE1_AXI_PERF_MON — Configures axi_perf_mon registers read permission in ree1 mode.\\ 0: can not be read \\ 1: can be read \\
  [1] READ_REE0_AXI_PERF_MON — Configures axi_perf_mon registers read permission in ree0 mode.\\ 0: can not be read \\ 1: can be read \\
  [0] READ_TEE_AXI_PERF_MON — Configures axi_perf_mon registers read permission in tee mode.\\ 0: can not be read \\ 1: can be read \\
0x200 HP_CPUPERI0_0 access per field — HP_CPUPERI0 PMS configuration & info register
  [9:8] HP_CPUPERI0_PMS_EXCEPTION_MODE ro — Represents the security mode when hp_cpuperi0 pms has been triggered.\\
  [7:2] HP_CPUPERI0_PMS_EXCEPTION_ID ro — Represents the master id when hp_cpuperi0 pms has been triggered.\\
  [1] HP_CPUPERI0_PMS_EXCEPTION_DET ro — Represents whether the hp_cpuperi0 pms has been triggered.\\ 0: No triggered\\ 1: Has been triggered\\
  [0] HP_CPUPERI0_PMS_EXCEPTION_CLR wo — Configures whether or not to clear hp_cpuperi0 peri_pms_record_reg.\\ 0: No clear\\ 1: Clear peri_pms_record_reg\\
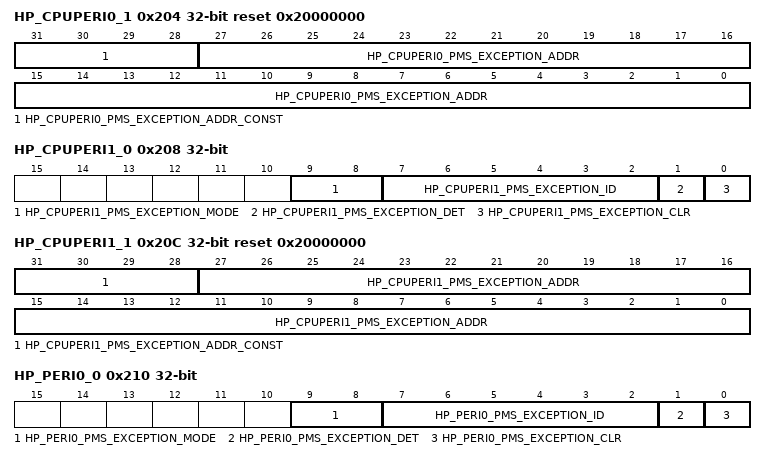
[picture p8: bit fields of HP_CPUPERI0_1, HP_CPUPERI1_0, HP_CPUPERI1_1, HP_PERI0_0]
0x204 HP_CPUPERI0_1 ro reset 0x20000000 — HP_CPUPERI0 PMS exception addr record register
  [31:28] HP_CPUPERI0_PMS_EXCEPTION_ADDR_CONST — Represents the access address (bit31~bit28) when hp_cpuperi0 pms has been triggered.\\
  [27:0] HP_CPUPERI0_PMS_EXCEPTION_ADDR — Represents the access address (bit27~bit0) when hp_cpuperi0 pms has been triggered.\\
0x208 HP_CPUPERI1_0 access per field — HP_CPUPERI1 PMS configuration & info register
  [9:8] HP_CPUPERI1_PMS_EXCEPTION_MODE ro — Represents the security mode when hp_cpuperi1 pms has been triggered.\\
  [7:2] HP_CPUPERI1_PMS_EXCEPTION_ID ro — Represents the master id when hp_cpuperi1 pms has been triggered.\\
  [1] HP_CPUPERI1_PMS_EXCEPTION_DET ro — Represents whether the hp_cpuperi1 pms has been triggered.\\ 0: No triggered\\ 1: Has been triggered\\
  [0] HP_CPUPERI1_PMS_EXCEPTION_CLR wo — Configures whether or not to clear hp_cpuperi1 peri_pms_record_reg.\\ 0: No clear\\ 1: Clear peri_pms_record_reg\\
0x20C HP_CPUPERI1_1 ro reset 0x20000000 — HP_CPUPERI1 PMS exception addr record register
  [31:28] HP_CPUPERI1_PMS_EXCEPTION_ADDR_CONST — Represents the access address (bit31~bit28) when hp_cpuperi1 pms has been triggered.\\
  [27:0] HP_CPUPERI1_PMS_EXCEPTION_ADDR — Represents the access address (bit27~bit0) when hp_cpuperi1 pms has been triggered.\\
0x210 HP_PERI0_0 access per field — HP_PERI0 PMS configuration & info register
  [9:8] HP_PERI0_PMS_EXCEPTION_MODE ro — Represents the security mode when hp_peri0 pms has been triggered.\\
  [7:2] HP_PERI0_PMS_EXCEPTION_ID ro — Represents the master id when hp_peri0 pms has been triggered.\\
  [1] HP_PERI0_PMS_EXCEPTION_DET ro — Represents whether the hp_peri0 pms has been triggered.\\ 0: No triggered\\ 1: Has been triggered\\
  [0] HP_PERI0_PMS_EXCEPTION_CLR wo — Configures whether or not to clear hp_peri0 peri_pms_record_reg.\\ 0: No clear\\ 1: Clear peri_pms_record_reg\\
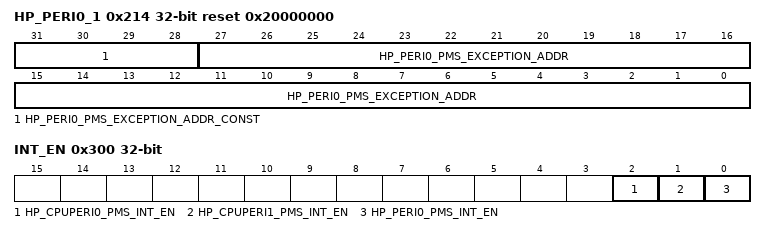
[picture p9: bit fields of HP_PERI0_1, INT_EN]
0x214 HP_PERI0_1 ro reset 0x20000000 — HP_PERI0 PMS exception addr record register
  [31:28] HP_PERI0_PMS_EXCEPTION_ADDR_CONST — Represents the access address (bit31~bit28) when hp_peri0 pms has been triggered.\\
  [27:0] HP_PERI0_PMS_EXCEPTION_ADDR — Represents the access address (bit27~bit0) when hp_peri0 pms has been triggered.\\
0x300 INT_EN — APM interrupt enable register
  [2] HP_CPUPERI0_PMS_INT_EN — Configures to enable hp_cpuperi0 pms interrupt.\\ 0: disable \\ 1: enable \\
  [1] HP_CPUPERI1_PMS_INT_EN — Configures to enable hp_cpuperi1 pms interrupt.\\ 0: disable \\ 1: enable \\
  [0] HP_PERI0_PMS_INT_EN — Configures to enable hp_peri0 pms interrupt.\\ 0: disable \\ 1: enable \\
0xFF0 BUS_ERR_CONF — Clock gating register
  [0] BUS_ERR_RESP_EN — Configures whether return error response to cpu when access blocked 0: disable error response \\ 1: enable error response \\
0xFF8 CLOCK_GATE reset 0x1 — Clock gating register
  [0] CLK_EN — Configures whether to keep the clock always on.\\ 0: enable automatic clock gating \\ 1: keep the clock always on \\
0xFFC DATE reset 0x2509230 — Version control register
  [27:0] DATE
